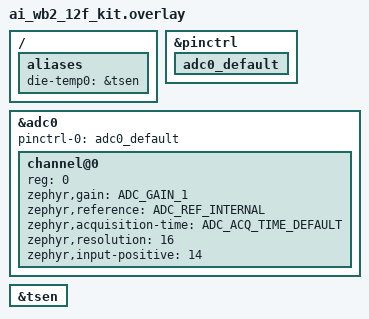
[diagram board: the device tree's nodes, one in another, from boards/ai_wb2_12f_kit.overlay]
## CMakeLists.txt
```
# Copyright (c) 2023 TOKITA Hiroshi
# SPDX-License-Identifier: Apache-2.0

cmake_minimum_required(VERSION 3.28.0)
find_package(Zephyr REQUIRED HINTS $ENV{ZEPHYR_BASE})
project(die_temp_polling)

FILE(GLOB app_sources src/*.c)
target_sources(app PRIVATE ${app_sources})
```

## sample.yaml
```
sample:
  description: CPU Die temperature polling sample
  name: die_temp_polling
tests:
  sample.sensor.die_temperature_polling:
    tags:
      - sensors
    filter: dt_alias_exists("die-temp0")
    integration_platforms:
      - stm32f3_disco
      - nucleo_h7a3zi_q
    harness: console
    harness_config:
      type: one_line
      regex:
        - "CPU Die temperature\\[[\\-A-Za-z0-9_@]+\\]: [1-9][0-9].[0-9] °C"
```

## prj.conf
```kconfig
CONFIG_SENSOR=y
CONFIG_ADC=y
CONFIG_PRINTK=y
CONFIG_CBPRINTF_FP_SUPPORT=y
```

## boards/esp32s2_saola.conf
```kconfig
CONFIG_REQUIRES_FULL_LIBC=y
```

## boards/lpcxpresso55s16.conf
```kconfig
CONFIG_TEMP_LPC=y
```

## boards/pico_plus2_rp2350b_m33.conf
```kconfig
CONFIG_ADC=y
```

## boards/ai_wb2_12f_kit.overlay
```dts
/*
 * Copyright The Zephyr Project Contributors
 * SPDX-License-Identifier: Apache-2.0
 */

#include <zephyr/dt-bindings/adc/adc.h>

&pinctrl {
	adc0_default: adc0_default {};
};

&adc0 {
	pinctrl-0 = <&adc0_default>;
	pinctrl-names = "default";
	status = "okay";

	channel@0 {
		reg = <0>;
		zephyr,gain = "ADC_GAIN_1";
		zephyr,reference = "ADC_REF_INTERNAL";
		zephyr,acquisition-time = <ADC_ACQ_TIME_DEFAULT>;
		zephyr,resolution = <16>;
		zephyr,input-positive = <14>;
	};
};

&tsen {
	status = "okay";
};

/ {
	aliases {
		die-temp0 = &tsen;
	};
};
```

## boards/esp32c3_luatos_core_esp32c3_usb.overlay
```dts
/*
 * Copyright (c) 2023, Hiroki Tada
 *
 * SPDX-License-Identifier: Apache-2.0
 *
 * Application overlay for creating temperature sensor device instance
 */

&coretemp {
	status = "okay";
};
```

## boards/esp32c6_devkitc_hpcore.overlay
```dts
/*
 * Copyright (c) 2025 Patrick Harböck
 *
 * SPDX-License-Identifier: Apache-2.0
 *
 * Application overlay for enabling temperature sensor device instance
 */

&coretemp {
	status = "okay";
};
```

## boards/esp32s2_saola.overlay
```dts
/*
 * Copyright (c) 2022 Espressif Systems (Shanghai) Co., Ltd.
 *
 * SPDX-License-Identifier: Apache-2.0
 *
 * Application overlay for creating temperature sensor device instance
 */

&coretemp {
	status = "okay";
};
```

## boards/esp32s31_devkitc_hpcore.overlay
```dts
/*
 * Copyright (c) 2026 Espressif Systems (Shanghai) Co., Ltd.
 *
 * SPDX-License-Identifier: Apache-2.0
 */

&coretemp {
	status = "okay";
};
```

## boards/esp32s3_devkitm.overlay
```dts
/*
 * Copyright (c) 2023 Espressif Systems (Shanghai) Co., Ltd.
 *
 * SPDX-License-Identifier: Apache-2.0
 *
 * Application overlay for enabling temperature sensor device instance
 */

&coretemp {
	status = "okay";
};
```

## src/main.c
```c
/*
 * Copyright (c) 2023 TOKITA Hiroshi
 *
 * SPDX-License-Identifier: Apache-2.0
 */

#include <zephyr/kernel.h>
#include <zephyr/device.h>
#include <zephyr/drivers/sensor.h>
#include <zephyr/sys/printk.h>

#define DIE_TEMP_ALIAS(i) DT_ALIAS(_CONCAT(die_temp, i))
#define DIE_TEMPERATURE_SENSOR(i, _)                                                               \
	IF_ENABLED(DT_NODE_EXISTS(DIE_TEMP_ALIAS(i)), (DEVICE_DT_GET(DIE_TEMP_ALIAS(i)),))

/* support up to 16 cpu die temperature sensors */
static const struct device *const sensors[] = {LISTIFY(16, DIE_TEMPERATURE_SENSOR, ())};

static int print_die_temperature(const struct device *dev)
{
	struct sensor_value val;
	int rc;

	/* fetch sensor samples */
	rc = sensor_sample_fetch(dev);
	if (rc) {
		printk("Failed to fetch sample (%d)\n", rc);
		return rc;
	}

	rc = sensor_channel_get(dev, SENSOR_CHAN_DIE_TEMP, &val);
	if (rc) {
		printk("Failed to get data (%d)\n", rc);
		return rc;
	}

	printk("CPU Die temperature[%s]: %.1f °C\n", dev->name, sensor_value_to_double(&val));
	return 0;
}

int main(void)
{
	int rc;

	for (size_t i = 0; i < ARRAY_SIZE(sensors); i++) {
		if (!device_is_ready(sensors[i])) {
			printk("sensor: device %s not ready.\n", sensors[i]->name);
			return 0;
		}
	}

	while (1) {
		for (size_t i = 0; i < ARRAY_SIZE(sensors); i++) {
			rc = print_die_temperature(sensors[i]);
			if (rc < 0) {
				return 0;
			}
		}
		k_msleep(300);
	}
	return 0;
}
```
